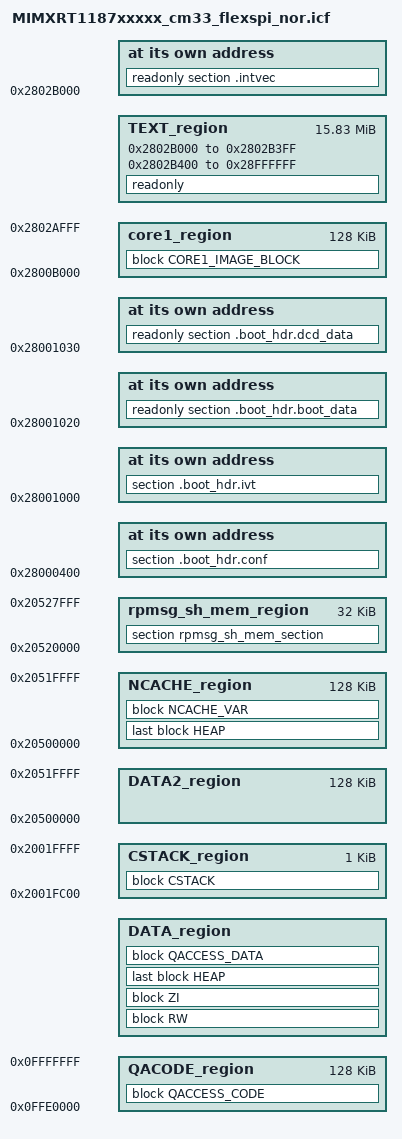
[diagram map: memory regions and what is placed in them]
/*
** ###################################################################
**     Processor:           MIMXRT1187CVM8B_cm33
**     Compiler:            IAR ANSI C/C++ Compiler for ARM
**     Reference manual:    IMXRT1180RM, Rev 0, 03/2021
**     Version:             rev. 0.1, 2021-03-09
**     Build:               b220221
**
**     Abstract:
**         Linker file for the IAR ANSI C/C++ Compiler for ARM
**
**     Copyright 2016 Freescale Semiconductor, Inc.
**     Copyright 2016-2022 NXP
**     All rights reserved.
**
**     SPDX-License-Identifier: BSD-3-Clause
**
**     http:                 www.nxp.com
**     mail:                 support@nxp.com
**
** ###################################################################
*/

define symbol __ram_vector_table_size__        =  isdefinedsymbol(__ram_vector_table__) ? 0x00000400 : 0;
define symbol __ram_vector_table_offset__      =  isdefinedsymbol(__ram_vector_table__) ? 0x000003FF : 0;

define symbol m_interrupts_start       = 0x2802B000;
define symbol m_interrupts_end         = 0x2802B3FF;

define symbol m_text_start             = 0x2802B400;
define symbol m_text_end               = 0x28FFFFFF;        /*0x0100_0000 16MB*/

define symbol m_interrupts_ram_start   = 0x20000000;
define symbol m_interrupts_ram_end     = 0x20000000 + __ram_vector_table_offset__;

define symbol m_data_start             = m_interrupts_ram_start + __ram_vector_table_size__;
define symbol m_data_end               = 0x2001FFFF;

define symbol m_data2_start            = 0x20500000;
define symbol m_data2_end              = 0x2051FFFF;

if (isdefinedsymbol(__use_shmem__)) {
  define exported symbol rpmsg_sh_mem_start      = 0x20520000;
  define exported symbol rpmsg_sh_mem_end        = 0x20527FFF;

  define exported symbol __RPMSG_SH_MEM_START    = rpmsg_sh_mem_start;
  define exported symbol __RPMSG_SH_MEM_SIZE     = rpmsg_sh_mem_end - rpmsg_sh_mem_start + 1;
}
define symbol m_ncache_start           = m_data2_start;
define symbol m_ncache_end             = m_data2_end;

define exported symbol __NCACHE_REGION_START   = m_ncache_start;
define exported symbol __NCACHE_REGION_SIZE    = m_ncache_end - m_ncache_start + 1;

define symbol m_qacode_start           = 0x0FFE0000;
define symbol m_qacode_end             = 0x0FFFFFFF;

define exported symbol m_boot_hdr_conf_start = 0x28000400;
define symbol m_boot_hdr_ivt_start           = 0x28001000;
define symbol m_boot_hdr_boot_data_start     = 0x28001020;
define symbol m_boot_hdr_dcd_data_start      = 0x28001030;
define exported symbol core1_image_start     = 0x2800B000;
define exported symbol core1_image_end       = 0x2802AFFF;

/* Sizes */
if (isdefinedsymbol(__stack_size__)) {
  define symbol __size_cstack__        = __stack_size__;
} else {
  define symbol __size_cstack__        = 0x0400;
}

if (isdefinedsymbol(__heap_size__)) {
  define symbol __size_heap__          = __heap_size__;
} else {
  define symbol __size_heap__          = 0x0400;
}

define exported symbol __VECTOR_TABLE          = m_interrupts_start;
define exported symbol __VECTOR_RAM            = isdefinedsymbol(__ram_vector_table__) ? m_interrupts_ram_start : m_interrupts_start;
define exported symbol __RAM_VECTOR_TABLE_SIZE = __ram_vector_table_size__;

define memory mem with size = 4G;
define region TEXT_region = mem:[from m_interrupts_start to m_interrupts_end]
                          | mem:[from m_text_start to m_text_end];
define region QACODE_region = mem:[from m_qacode_start to m_qacode_end];
define region DATA_region = mem:[from m_data_start to m_data_end-__size_cstack__];
define region DATA2_region = mem:[from m_data2_start to m_data2_end];
define region CSTACK_region = mem:[from m_data_end-__size_cstack__+1 to m_data_end];
if (isdefinedsymbol(__use_shmem__)) {
  define region rpmsg_sh_mem_region     = mem:[from rpmsg_sh_mem_start to rpmsg_sh_mem_end];
}
define region NCACHE_region = mem:[from m_ncache_start to m_ncache_end];
define block RW        { readwrite };
define block ZI        { zi };
define block NCACHE_VAR    { section NonCacheable , section NonCacheable.init };
define block CSTACK    with alignment = 8, size = __size_cstack__   { };
define block HEAP      with alignment = 8, size = __size_heap__     { };
define block QACCESS_CODE  { section CodeQuickAccess };
define block QACCESS_DATA  { section DataQuickAccess };

define region core1_region = mem:[from core1_image_start to core1_image_end];
define block CORE1_IMAGE_BLOCK          { section  __core1_image };

initialize by copy { readwrite, section .textrw, section CodeQuickAccess, section DataQuickAccess };
do not initialize  { section .noinit };
if (isdefinedsymbol(__use_shmem__)) {
  do not initialize  { section rpmsg_sh_mem_section };
}

place at address mem: m_interrupts_start    { readonly section .intvec };
place at address mem: m_boot_hdr_conf_start { section .boot_hdr.conf };
place at address mem: m_boot_hdr_ivt_start { section .boot_hdr.ivt };
place at address mem: m_boot_hdr_boot_data_start { readonly section .boot_hdr.boot_data };
place at address mem: m_boot_hdr_dcd_data_start { readonly section .boot_hdr.dcd_data };

keep{ section .boot_hdr.conf, section .boot_hdr.ivt, section .boot_hdr.boot_data, section .boot_hdr.dcd_data };

place in TEXT_region                        { readonly };
place in DATA_region                        { block RW };
place in DATA_region                        { block ZI };
if (isdefinedsymbol(__heap_noncacheable__)) {
  place in NCACHE_region                    { last block HEAP };
} else {
  place in DATA_region                      { last block HEAP };
}
place in CSTACK_region                      { block CSTACK };
place in NCACHE_region                      { block NCACHE_VAR };
place in QACODE_region                      { block QACCESS_CODE };
place in DATA_region                        { block QACCESS_DATA };
if (isdefinedsymbol(__use_shmem__)) {
  place in rpmsg_sh_mem_region                { section rpmsg_sh_mem_section };
}
place in core1_region                       { block CORE1_IMAGE_BLOCK };
